# STM32F30xxx register map
File version: 1.0
Registers are 32-bit, read-write, reset 0x0 unless marked. A register's access mark holds for its fields unless they carry their own. Offsets are from the block's base; lines under a group give offsets from that group; [hi:lo] are bit positions; {n}, {i} and the like mark numbered series; 'fields as' and 'values as' point back to an identical list; <NAME> marks a mode.

## Memory map
0x40000000 TIM2 size 0x400 — General purpose timer
0x40000400 TIM3 size 0x400
0x40000800 TIM4 size 0x400
0x40001000 TIM6 size 0x400 — Basic timers
0x40001400 TIM7 size 0x400
0x40002800 RTC size 0x400 — Real-time clock
0x40002C00 WWDG size 0x400 — Window watchdog
0x40003000 IWDG size 0x400 — Independent watchdog
0x40003400 I2S2ext size 0x400
0x40003800 SPI2 size 0x400
0x40003C00 SPI3 size 0x400
0x40004000 I2S3ext size 0x400
0x40004400 USART2 size 0x400
0x40004800 USART3 size 0x400
0x40004C00 UART4 size 0x400
0x40005000 UART5 size 0x400
0x40005400 I2C1 size 0x400 — Inter-integrated circuit
0x40005800 I2C2 size 0x400
0x40005C00 USB_FS size 0x400 — Universal serial bus full-speed device interface
0x40006400 CAN size 0x400 — Controller area network
0x40007000 PWR size 0x400 — Power control
0x40007400 DAC size 0x400 — Digital-to-analog converter
0x40010000 SYSCFG size 0x19 — System configuration controller
0x4001001C COMP size 0x19 — Comparator
0x40010038 OPAMP size 0x3C8 — Operational amplifier
0x40010400 EXTI size 0x400 — External interrupt/event controller
0x40012C00 TIM1 size 0x400 — Advanced timer
0x40013000 SPI1 size 0x400 — Serial peripheral interface/Inter-IC sound
0x40013400 TIM8 size 0x400 — Advanced-timers
0x40013800 USART1 size 0x400 — Universal synchronous asynchronous receiver transmitter
0x40014000 TIM15 size 0x400 — General purpose timers
0x40014400 TIM16 size 0x400 — General-purpose-timers
0x40014800 TIM17 size 0x400 — General purpose timer
0x40020000 DMA1 size 0x400 — DMA controller 1
0x40020400 DMA2 size 0x400
0x40021000 RCC size 0x400 — Reset and clock control
0x40022000 Flash size 0x400
0x40023000 CRC size 0x400 — cyclic redundancy check calculation unit
0x40024000 TSC size 0x400 — Touch sensing controller
0x48000000 GPIOA size 0x400 — General-purpose I/Os
0x48000400 GPIOB size 0x400 — General-purpose I/Os
0x48000800 GPIOC size 0x400
0x48000C00 GPIOD size 0x400
0x48001000 GPIOE size 0x400
0x48001400 GPIOF size 0x400
0x50000000 ADC1_2 size 0x400 — Analog-to-Digital Converter
0x50000400 ADC3_4 size 0x400
0xE000E000 NVIC size 0x1001 — Nested Vectored Interrupt Controller
0xE000ED88 FPU size 0x200 — Floting point unit
0xE0042000 DBGMCU size 0x400 — Debug support

## GPIOA — General-purpose I/Os
Base 0x48000000
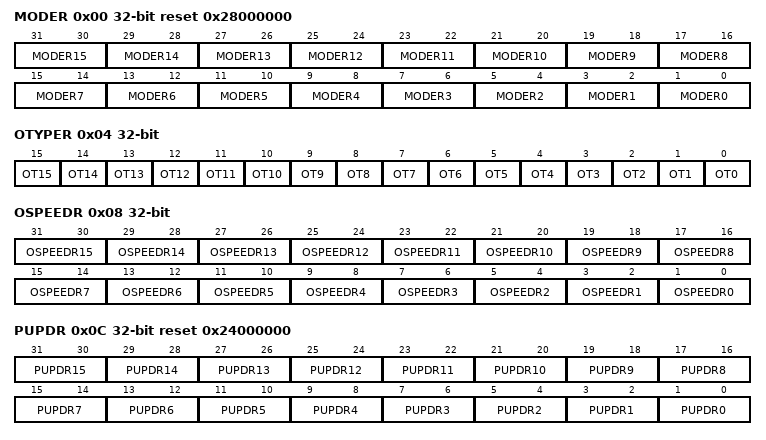
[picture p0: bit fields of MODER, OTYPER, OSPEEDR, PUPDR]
0x00 MODER reset 0x28000000 — GPIO port mode register
  [2n+1:2n] MODER{n} (n=0..15) — Port x configuration bits (y = 0..15)
0x04 OTYPER — GPIO port output type register
  [n] OT{n} (n=0..15) — Port x configuration bits (y = 0..15)
0x08 OSPEEDR — GPIO port output speed register
  [2n+1:2n] OSPEEDR{n} (n=0..15) — Port x configuration bits (y = 0..15)
0x0C PUPDR reset 0x24000000 — GPIO port pull-up/pull-down register
  [2n+1:2n] PUPDR{n} (n=0..15) — Port x configuration bits (y = 0..15)
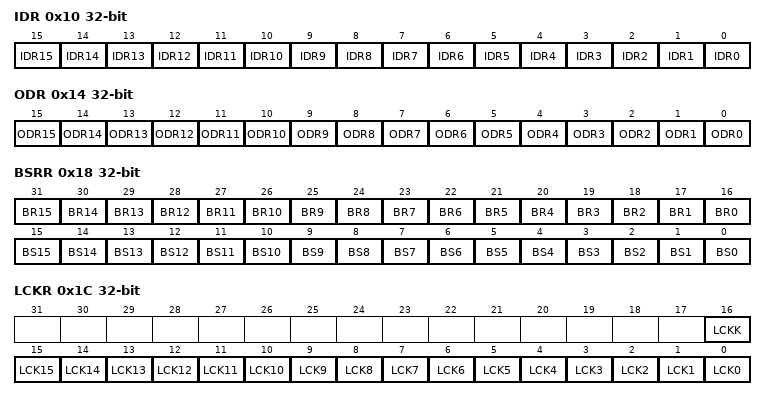
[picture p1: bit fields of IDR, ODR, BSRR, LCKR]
0x10 IDR ro — GPIO port input data register
  [n] IDR{n} (n=0..15) — Port input data (y = 0..15)
0x14 ODR — GPIO port output data register
  [n] ODR{n} (n=0..15) — Port output data (y = 0..15)
0x18 BSRR wo — GPIO port bit set/reset register
  [n+16] BR{n} (n=1..15) — Port x reset bit y (y = 0..15)
  [16] BR0 — Port x set bit y (y= 0..15)
  [n] BS{n} (n=0..15) — Port x set bit y (y= 0..15)
0x1C LCKR — GPIO port configuration lock register
  [16] LCKK — Lok Key
  [n] LCK{n} (n=0..15) — Port x lock bit y (y= 0..15)
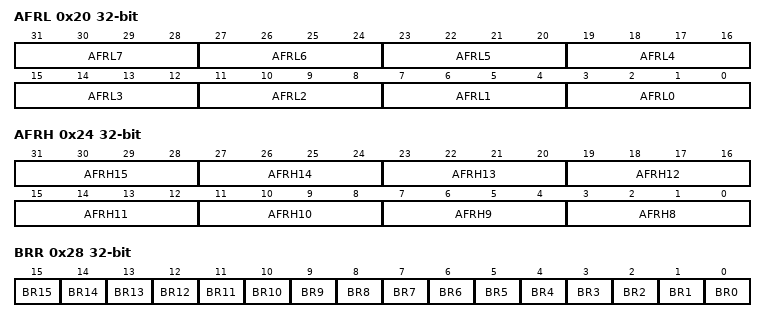
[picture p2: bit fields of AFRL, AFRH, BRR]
0x20 AFRL — GPIO alternate function low register
  [4n+3:4n] AFRL{n} (n=0..7) — Alternate function selection for port x bit y (y = 0..7)
0x24 AFRH — GPIO alternate function high register
  [4n-29:4n-32] AFRH{n} (n=8..15) — Alternate function selection for port x bit y (y = 8..15)
0x28 BRR wo — Port bit reset register
  [n] BR{n} (n=0..15) — Port x Reset bit y

## GPIOB — General-purpose I/Os
Base 0x48000400
Same registers: GPIOC 0x48000800, GPIOD 0x48000C00, GPIOE 0x48001000, GPIOF 0x48001400
Registers as GPIOA; these are added or differ:
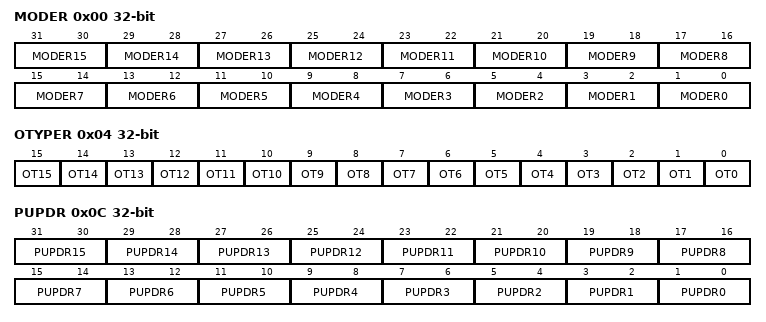
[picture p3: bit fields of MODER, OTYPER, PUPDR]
0x00 MODER — GPIO port mode register
  [2n+1:2n] MODER{n} (n=0..15) — Port x configuration bits (y = 0..15)
0x04 OTYPER — GPIO port output type register
  [n] OT{n} (n=0..15) — Port x configuration bit {n}
0x0C PUPDR — GPIO port pull-up/pull-down register
  [2n+1:2n] PUPDR{n} (n=0..15) — Port x configuration bits (y = 0..15)
